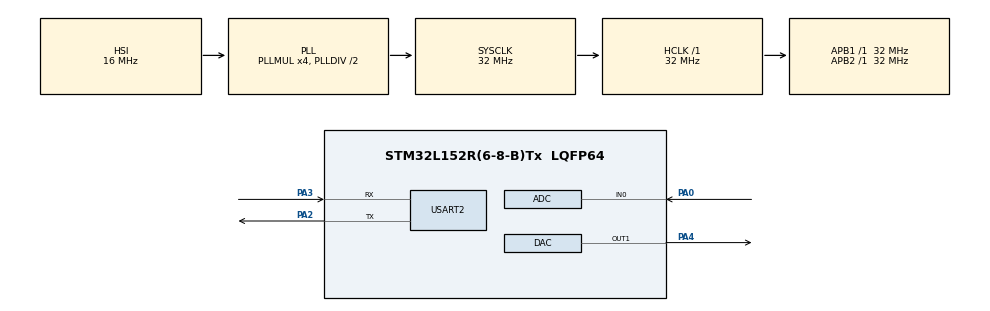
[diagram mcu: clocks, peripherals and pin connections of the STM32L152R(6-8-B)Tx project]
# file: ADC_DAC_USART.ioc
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ADC.Channel-0\#ChannelRegularConversion=ADC_CHANNEL_0
ADC.ContinuousConvMode=ENABLE
ADC.EOCSelection=ADC_EOC_SEQ_CONV
ADC.NbrOfConversionFlag=1
ADC.Rank-0\#ChannelRegularConversion=1
ADC.Resolution=ADC_RESOLUTION_8B
ADC.SamplingTime-0\#ChannelRegularConversion=ADC_SAMPLETIME_4CYCLES
Dma.Request0=USART2_TX
Dma.USART2_TX.0.Direction=DMA_MEMORY_TO_PERIPH
Dma.USART2_TX.0.Instance=DMA1_Channel7
Dma.USART2_TX.0.MemDataAlignment=DMA_MDATAALIGN_BYTE
Dma.USART2_TX.0.MemInc=DMA_MINC_ENABLE
Dma.USART2_TX.0.Mode=DMA_CIRCULAR
Dma.USART2_TX.0.PeriphDataAlignment=DMA_PDATAALIGN_BYTE
Dma.USART2_TX.0.PeriphInc=DMA_PINC_DISABLE
Dma.USART2_TX.0.Priority=DMA_PRIORITY_LOW
Mcu.Family=STM32L1
Mcu.Name=STM32L152R(6-8-B)Tx
Mcu.Package=LQFP64
NVIC.DMA1_Channel7_IRQn=true\:0\:0\:false\:false\:true
NVIC.PriorityGroup=NVIC_PRIORITYGROUP_4
PA0-WKUP1.Mode=IN0
PA0-WKUP1.Signal=ADC_IN0
PA2.Mode=Asynchronous
PA2.Signal=USART2_TX
PA3.Mode=Asynchronous
PA3.Signal=USART2_RX
PA4.Signal=COMP_DAC1_group
ProjectManager.HeapSize=0x200
ProjectManager.StackSize=0x400
ProjectManager.TargetToolchain=MDK-ARM V5
RCC.AHBFreq_Value=32000000
RCC.APB1Freq_Value=32000000
RCC.APB1TimFreq_Value=32000000
RCC.APB2Freq_Value=32000000
RCC.APB2TimFreq_Value=32000000
RCC.HCLKFreq_Value=32000000
RCC.HSE_VALUE=24000000
RCC.HSI_VALUE=16000000
RCC.LSE_VALUE=32768
RCC.MSI_VALUE=2097000
RCC.PLLMUL=RCC_PLL_MUL4
RCC.SYSCLKFreq_VALUE=32000000
RCC.SYSCLKSource=RCC_SYSCLKSOURCE_PLLCLK
RCC.USBOutput=32000000
RCC.VCOOutputFreq_Value=64000000
SH.COMP_DAC1_group.0=DAC_OUT1,DAC_OUT1
board=ADC_DAC_USART

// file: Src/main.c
/**
  ******************************************************************************
  * File Name          : main.c
  * Description        : Main program body
  ******************************************************************************
  *
  * COPYRIGHT(c) 2016 STMicroelectronics
  *
  * Redistribution and use in source and binary forms, with or without modification,
  * are permitted provided that the following conditions are met:
  *   1. Redistributions of source code must retain the above copyright notice,
  *      this list of conditions and the following disclaimer.
  *   2. Redistributions in binary form must reproduce the above copyright notice,
  *      this list of conditions and the following disclaimer in the documentation
  *      and/or other materials provided with the distribution.
  *   3. Neither the name of STMicroelectronics nor the names of its contributors
  *      may be used to endorse or promote products derived from this software
  *      without specific prior written permission.
  *
  * THIS SOFTWARE IS PROVIDED BY THE COPYRIGHT HOLDERS AND CONTRIBUTORS "AS IS"
  * AND ANY EXPRESS OR IMPLIED WARRANTIES, INCLUDING, BUT NOT LIMITED TO, THE
  * IMPLIED WARRANTIES OF MERCHANTABILITY AND FITNESS FOR A PARTICULAR PURPOSE ARE
  * DISCLAIMED. IN NO EVENT SHALL THE COPYRIGHT HOLDER OR CONTRIBUTORS BE LIABLE
  * FOR ANY DIRECT, INDIRECT, INCIDENTAL, SPECIAL, EXEMPLARY, OR CONSEQUENTIAL
  * DAMAGES (INCLUDING, BUT NOT LIMITED TO, PROCUREMENT OF SUBSTITUTE GOODS OR
  * SERVICES; LOSS OF USE, DATA, OR PROFITS; OR BUSINESS INTERRUPTION) HOWEVER
  * CAUSED AND ON ANY THEORY OF LIABILITY, WHETHER IN CONTRACT, STRICT LIABILITY,
  * OR TORT (INCLUDING NEGLIGENCE OR OTHERWISE) ARISING IN ANY WAY OUT OF THE USE
  * OF THIS SOFTWARE, EVEN IF ADVISED OF THE POSSIBILITY OF SUCH DAMAGE.
  *
  ******************************************************************************
  */
#include "stm32l1xx_hal.h"

ADC_HandleTypeDef hadc;

DAC_HandleTypeDef hdac;

UART_HandleTypeDef huart2;
DMA_HandleTypeDef hdma_usart2_tx;

/* USER CODE BEGIN PV */
/* Private variables ---------------------------------------------------------*/
uint16_t i,j;
uint8_t buffin[256],buffout[256];
/* USER CODE END PV */

void SystemClock_Config(void);
static void MX_GPIO_Init(void);
static void MX_DMA_Init(void);
static void MX_ADC_Init(void);
static void MX_DAC_Init(void);
static void MX_USART2_UART_Init(void);

/* USER CODE BEGIN PFP */
/* Private function prototypes -----------------------------------------------*/

/* USER CODE END PFP */

int main(void)
{

  /* MCU Configuration----------------------------------------------------------*/

  /* Reset of all peripherals, Initializes the Flash interface and the Systick. */
  HAL_Init();

  /* Configure the system clock */
  SystemClock_Config();

  /* Initialize all configured peripherals */
  MX_GPIO_Init();
  MX_DMA_Init();
  MX_ADC_Init();
  MX_DAC_Init();
  MX_USART2_UART_Init();

  /* USER CODE BEGIN 2 */
for (i=0;i<256;i++) buffin[i]=i;
HAL_DAC_Start(&hdac, DAC_CHANNEL_1);
HAL_ADC_Start(&hadc);
HAL_UART_Transmit_DMA(&huart2, (uint8_t *)buffout, 256);
  /* USER CODE END 2 */

  /* Infinite loop */
  /* USER CODE BEGIN WHILE */
  while (1)
  {
		i++;
		if(i>255) i=0;
		HAL_DAC_SetValue(&hdac, DAC_CHANNEL_1, DAC_ALIGN_8B_R, buffin[i]);
		for (j=0;j<30000;j++);
		for (j=0;j<30000;j++);		//tijdrekken
		buffout[i]=HAL_ADC_GetValue(&hadc);
		int temp = buffout[i];
		HAL_UART_Transmit(&huart2, (uint8_t *)temp,1,5);
  /* USER CODE END WHILE */

  }

}

/** System Clock Configuration
*/
void SystemClock_Config(void)
{

  RCC_OscInitTypeDef RCC_OscInitStruct;
  RCC_ClkInitTypeDef RCC_ClkInitStruct;

  __HAL_RCC_PWR_CLK_ENABLE();

  __HAL_PWR_VOLTAGESCALING_CONFIG(PWR_REGULATOR_VOLTAGE_SCALE1);

  RCC_OscInitStruct.OscillatorType = RCC_OSCILLATORTYPE_HSI;
  RCC_OscInitStruct.HSIState = RCC_HSI_ON;
  RCC_OscInitStruct.HSICalibrationValue = 16;
  RCC_OscInitStruct.PLL.PLLState = RCC_PLL_ON;
  RCC_OscInitStruct.PLL.PLLSource = RCC_PLLSOURCE_HSI;
  RCC_OscInitStruct.PLL.PLLMUL = RCC_PLL_MUL4;
  RCC_OscInitStruct.PLL.PLLDIV = RCC_PLL_DIV2;
  HAL_RCC_OscConfig(&RCC_OscInitStruct);

  RCC_ClkInitStruct.ClockType = RCC_CLOCKTYPE_HCLK|RCC_CLOCKTYPE_SYSCLK
                              |RCC_CLOCKTYPE_PCLK1|RCC_CLOCKTYPE_PCLK2;
  RCC_ClkInitStruct.SYSCLKSource = RCC_SYSCLKSOURCE_PLLCLK;
  RCC_ClkInitStruct.AHBCLKDivider = RCC_SYSCLK_DIV1;
  RCC_ClkInitStruct.APB1CLKDivider = RCC_HCLK_DIV1;
  RCC_ClkInitStruct.APB2CLKDivider = RCC_HCLK_DIV1;
  HAL_RCC_ClockConfig(&RCC_ClkInitStruct, FLASH_LATENCY_1);

  HAL_SYSTICK_Config(HAL_RCC_GetHCLKFreq()/1000);

  HAL_SYSTICK_CLKSourceConfig(SYSTICK_CLKSOURCE_HCLK);

  /* SysTick_IRQn interrupt configuration */
  HAL_NVIC_SetPriority(SysTick_IRQn, 0, 0);
}

/* ADC init function */
void MX_ADC_Init(void)
{

  ADC_ChannelConfTypeDef sConfig;

    /**Configure the global features of the ADC (Clock, Resolution, Data Alignment and number of conversion)
    */
  hadc.Instance = ADC1;
  hadc.Init.ClockPrescaler = ADC_CLOCK_ASYNC_DIV1;
  hadc.Init.Resolution = ADC_RESOLUTION_8B;
  hadc.Init.DataAlign = ADC_DATAALIGN_RIGHT;
  hadc.Init.ScanConvMode = ADC_SCAN_DISABLE;
  hadc.Init.EOCSelection = ADC_EOC_SEQ_CONV;
  hadc.Init.LowPowerAutoWait = ADC_AUTOWAIT_DISABLE;
  hadc.Init.LowPowerAutoPowerOff = ADC_AUTOPOWEROFF_DISABLE;
  hadc.Init.ChannelsBank = ADC_CHANNELS_BANK_A;
  hadc.Init.ContinuousConvMode = ENABLE;
  hadc.Init.NbrOfConversion = 1;
  hadc.Init.DiscontinuousConvMode = DISABLE;
  hadc.Init.ExternalTrigConv = ADC_SOFTWARE_START;
  hadc.Init.ExternalTrigConvEdge = ADC_EXTERNALTRIGCONVEDGE_NONE;
  hadc.Init.DMAContinuousRequests = DISABLE;
  HAL_ADC_Init(&hadc);

    /**Configure for the selected ADC regular channel its corresponding rank in the sequencer and its sample time.
    */
  sConfig.Channel = ADC_CHANNEL_0;
  sConfig.Rank = 1;
  sConfig.SamplingTime = ADC_SAMPLETIME_4CYCLES;
  HAL_ADC_ConfigChannel(&hadc, &sConfig);

}

/* DAC init function */
void MX_DAC_Init(void)
{

  DAC_ChannelConfTypeDef sConfig;

    /**DAC Initialization
    */
  hdac.Instance = DAC;
  HAL_DAC_Init(&hdac);

    /**DAC channel OUT1 config
    */
  sConfig.DAC_Trigger = DAC_TRIGGER_NONE;
  sConfig.DAC_OutputBuffer = DAC_OUTPUTBUFFER_ENABLE;
  HAL_DAC_ConfigChannel(&hdac, &sConfig, DAC_CHANNEL_1);

}

/* USART2 init function */
void MX_USART2_UART_Init(void)
{

  huart2.Instance = USART2;
  huart2.Init.BaudRate = 115200;
  huart2.Init.WordLength = UART_WORDLENGTH_8B;
  huart2.Init.StopBits = UART_STOPBITS_1;
  huart2.Init.Parity = UART_PARITY_NONE;
  huart2.Init.Mode = UART_MODE_TX_RX;
  huart2.Init.HwFlowCtl = UART_HWCONTROL_NONE;
  huart2.Init.OverSampling = UART_OVERSAMPLING_16;
  HAL_UART_Init(&huart2);

}

void MX_DMA_Init(void)
{
  /* DMA controller clock enable */
  __HAL_RCC_DMA1_CLK_ENABLE();

  /* DMA interrupt init */
  /* DMA1_Channel7_IRQn interrupt configuration */
  HAL_NVIC_SetPriority(DMA1_Channel7_IRQn, 0, 0);
  HAL_NVIC_EnableIRQ(DMA1_Channel7_IRQn);

}

/** Pinout Configuration
*/
void MX_GPIO_Init(void)
{

  /* GPIO Ports Clock Enable */
  __HAL_RCC_GPIOA_CLK_ENABLE();

}

/************************ (C) COPYRIGHT STMicroelectronics *****END OF FILE****/
